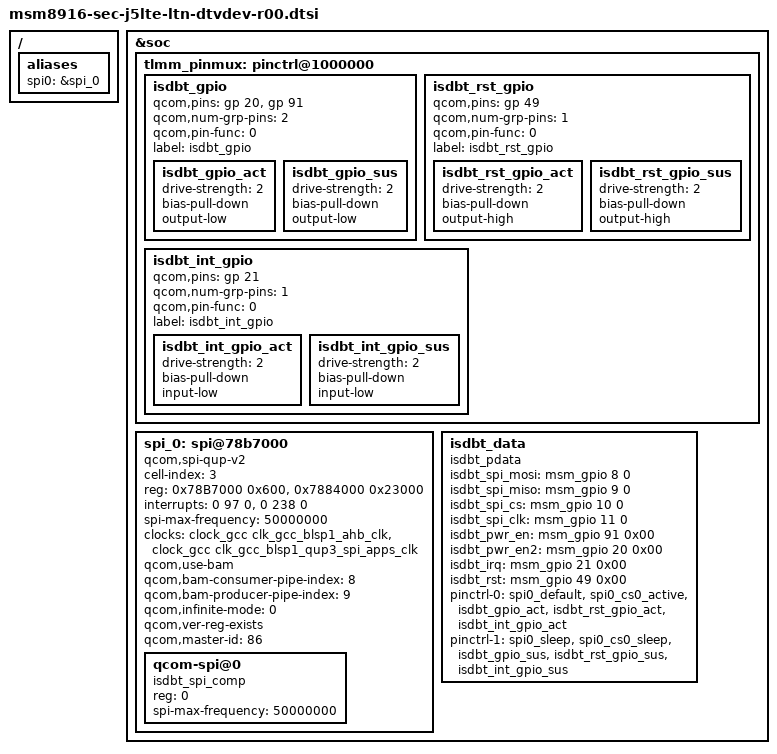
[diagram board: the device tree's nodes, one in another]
/* Copyright (c) 2012-2013, The Linux Foundation. All rights reserved.
 *
 * This program is free software; you can redistribute it and/or modify
 * it under the terms of the GNU General Public License version 2 and
 * only version 2 as published by the Free Software Foundation.
 *
 * This program is distributed in the hope that it will be useful,
 * but WITHOUT ANY WARRANTY; without even the implied warranty of
 * MERCHANTABILITY or FITNESS FOR A PARTICULAR PURPOSE.  See the
 * GNU General Public License for more details.
 */

/{
	aliases {
		spi0 = &spi_0;
	};
};

&soc {
	tlmm_pinmux: pinctrl@1000000 {

		isdbt_gpio {
			qcom,pins = <&gp 20>, <&gp 91>;
			qcom,num-grp-pins = <2>;
			qcom,pin-func = <0>;
		    label = "isdbt_gpio";

			isdbt_gpio_act: isdbt_gpio_act {
				drive-strength = <2>; /* 2 MA */
				bias-pull-down; /* PULL DOWN */
				output-low;
			};
			isdbt_gpio_sus: isdbt_gpio_sus {
				drive-strength = <2>; /* 2 MA */
				bias-pull-down; /* PULL DOWN */
				output-low;
			};
		};

		isdbt_rst_gpio {
			qcom,pins = <&gp 49>;
			qcom,num-grp-pins = <1>;
			qcom,pin-func = <0>;
		    label = "isdbt_rst_gpio";

			isdbt_rst_gpio_act: isdbt_rst_gpio_act {
				drive-strength = <2>; /* 2 MA */
				bias-pull-down; /* PULL DOWN */
				output-high;
			};
			isdbt_rst_gpio_sus: isdbt_rst_gpio_sus {
				drive-strength = <2>; /* 2 MA */
				bias-pull-down; /* PULL DOWN */
				output-high;
			};
		};

		isdbt_int_gpio {
			qcom,pins = <&gp 21>;
			qcom,num-grp-pins = <1>;
			qcom,pin-func = <0>;
		    label = "isdbt_int_gpio";

			isdbt_int_gpio_act: isdbt_int_gpio_act {
				drive-strength = <2>; /* 2 MA */
				bias-pull-down; /* PULL DOWN */
				input-low;
			};
			isdbt_int_gpio_sus: isdbt_int_gpio_sus {
				drive-strength = <2>; /* 2 MA */
				bias-pull-down; /* PULL DOWN */
				input-low;
			};
		};
	};

	spi_0: spi@78b7000 { /* BLSP1 QUP3 */
		compatible = "qcom,spi-qup-v2";
		cell-index = <3>;
		#address-cells = <1>;
		#size-cells = <0>;
		reg-names = "spi_physical", "spi_bam_physical";
		reg = <0x78B7000 0x600>, <0x7884000 0x23000>;
		interrupt-names = "spi_irq", "spi_bam_irq";
		interrupts = <0 97 0>, <0 238 0>;
		spi-max-frequency = <50000000>;
		clocks = <&clock_gcc clk_gcc_blsp1_ahb_clk>,
			 <&clock_gcc clk_gcc_blsp1_qup3_spi_apps_clk>;
		clock-names = "iface_clk", "core_clk";

		/*
		qcom,gpio-mosi = <&msm_gpio 8 0>;
		qcom,gpio-miso = <&msm_gpio 9 0>;
		qcom,gpio-cs0 = <&msm_gpio 10 0>;
		qcom,gpio-clk = <&msm_gpio 11 0>;
		*/

		qcom,use-bam;
		//qcom,use-pinctrl;
		qcom,bam-consumer-pipe-index = <8>;
		qcom,bam-producer-pipe-index = <9>;
		qcom,infinite-mode = <0>;
		qcom,ver-reg-exists;
		qcom,master-id = <86>;

		status = "ok";
		qcom-spi@0 {
			compatible = "isdbt_spi_comp";
			reg = <0>;
			spi-max-frequency = <50000000>;
		};
	};

	isdbt_data {
		compatible = "isdbt_pdata";
		isdbt_spi_mosi = <&msm_gpio 8 0>;
		isdbt_spi_miso = <&msm_gpio 9 0>;
		isdbt_spi_cs = <&msm_gpio 10 0>;
		isdbt_spi_clk = <&msm_gpio 11 0>;
		isdbt_pwr_en = <&msm_gpio 91 0x00>;
		isdbt_pwr_en2 = <&msm_gpio 20 0x00>;
		isdbt_irq = <&msm_gpio 21 0x00>;
		isdbt_rst = <&msm_gpio 49 0x00>;
		pinctrl-names = "isdbt_gpio_active", "isdbt_gpio_suspend";
		pinctrl-0 = <&spi0_default &spi0_cs0_active &isdbt_gpio_act &isdbt_rst_gpio_act &isdbt_int_gpio_act>;
		pinctrl-1 = <&spi0_sleep &spi0_cs0_sleep &isdbt_gpio_sus &isdbt_rst_gpio_sus &isdbt_int_gpio_sus>;
	};

};
